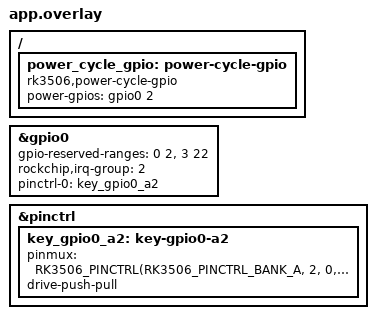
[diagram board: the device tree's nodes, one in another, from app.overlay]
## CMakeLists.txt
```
# SPDX-License-Identifier: Apache-2.0

cmake_minimum_required(VERSION 3.20.0)

get_filename_component(RK3506_ZEPHYR_ROOT
  "${CMAKE_CURRENT_SOURCE_DIR}/../../../.."
  ABSOLUTE
)
# Same compatibility glue as rk3506_pingpong: SDK direct builds invoke this
# as a freestanding app.  NOTE: do NOT append RK3506_ZEPHYR_ROOT to
# EXTRA_ZEPHYR_MODULES here — the repo root exposes zephyr/{CMakeLists.txt,
# Kconfig}, so west's module scanner treats it as a module and re-sources
# the main Kconfig recursively.  BOARD_ROOT/SOC_ROOT/DTS_ROOT below already
# make the board/soc/dts visible.
list(APPEND BOARD_ROOT "${RK3506_ZEPHYR_ROOT}")
list(APPEND SOC_ROOT "${RK3506_ZEPHYR_ROOT}")
list(APPEND DTS_ROOT "${RK3506_ZEPHYR_ROOT}")

find_package(Zephyr REQUIRED HINTS $ENV{ZEPHYR_BASE})
project(gpio_power_cycle)

target_include_directories(app PRIVATE
  src
)

target_sources(app PRIVATE
  src/main.c
)
```

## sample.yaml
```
sample:
  name: RK3506 GPIO0_A2 one-shot key signal
  description: >
    Uses the Zephyr GPIO driver to drive GPIO0_A2:
    HIGH for 50 s -> LOW for 250 ms -> HIGH for 20 s -> LOW for 250 ms -> HIGH indefinitely,
    once per application boot.
tests:
  sample.rk3506.gpio_power_cycle:
    build_only: true
    platform_allow:
      - ok3506b_s12_amp_uart1
    integration_platforms:
      - ok3506b_s12_amp_uart1
```

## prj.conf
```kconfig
# SPDX-License-Identifier: Apache-2.0

CONFIG_SERIAL=y
CONFIG_CONSOLE=y
CONFIG_UART_CONSOLE=y
CONFIG_PRINTK=y
CONFIG_LOG=y

CONFIG_GPIO=y
CONFIG_GPIO_RK3506=y

# This application does not create an RPMsg endpoint.
CONFIG_SOC_RK3506_RPMSG_LITE=n
```

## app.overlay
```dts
/*
 * Copyright (c) 2026
 * SPDX-License-Identifier: Apache-2.0
 *
 * GPIO0_A2 = gpio0 pin 2. Only this pin is assigned to the application.
 */

#include <zephyr/dt-bindings/gpio/gpio.h>

/ {
	power_cycle_gpio: power-cycle-gpio {
		compatible = "rk3506,power-cycle-gpio";
		power-gpios = <&gpio0 2 GPIO_ACTIVE_HIGH>;
	};
};

&gpio0 {
	status = "okay";
	gpio-reserved-ranges = <0 2>, <3 22>;
	rockchip,irq-group = <2>;
	pinctrl-0 = <&key_gpio0_a2>;
	pinctrl-names = "default";
};

&pinctrl {
	key_gpio0_a2: key-gpio0-a2 {
		pinmux = <RK3506_PINCTRL(RK3506_PINCTRL_BANK_A, 2, 0, 0)>;
		drive-push-pull;
	};
};
```

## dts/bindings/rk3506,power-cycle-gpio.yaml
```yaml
# Copyright (c) 2026
# SPDX-License-Identifier: Apache-2.0

description: |
    Single GPIO output used as an external power-controller signal for
    cold power-cycle stress testing.

compatible: "rk3506,power-cycle-gpio"

properties:
  power-gpios:
    type: phandle-array
    required: true
    description: |
      The GPIO that signals the external power controller.
```

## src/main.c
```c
/*
 * Copyright (c) 2026
 * SPDX-License-Identifier: Apache-2.0
 *
 * One-shot key signal: HIGH 50 s, LOW 250 ms, HIGH 20 s, LOW 250 ms, then HIGH.
 * Timing starts when the application configures the GPIO output.
 */

#include <inttypes.h>

#include <zephyr/drivers/gpio.h>
#include <zephyr/kernel.h>
#include <zephyr/logging/log.h>

LOG_MODULE_REGISTER(gpio_power_cycle, LOG_LEVEL_INF);

#if !DT_NODE_EXISTS(DT_NODELABEL(power_cycle_gpio))
#error "power-cycle gpio node missing from devicetree"
#endif

static const struct gpio_dt_spec sig =
	GPIO_DT_SPEC_GET(DT_NODELABEL(power_cycle_gpio), power_gpios);

static int set_level(int level, int64_t start)
{
	int ret = gpio_pin_set_dt(&sig, level);

	if (ret) {
		LOG_ERR("gpio_pin_set_dt(%d) failed: %d", level, ret);
		return ret;
	}
	LOG_INF("t=%" PRId64 " ms GPIO0_A2 -> %s",
		k_uptime_get() - start, level ? "HIGH" : "LOW");
	return 0;
}

int main(void)
{
	int ret;
	int64_t start;
	int64_t phase_start;

	if (!gpio_is_ready_dt(&sig)) {
		LOG_ERR("GPIO device not ready");
		return -ENODEV;
	}

	/* Preload HIGH before enabling the output direction. */
	ret = gpio_pin_configure_dt(&sig, GPIO_OUTPUT_HIGH);
	if (ret) {
		LOG_ERR("configure failed: %d", ret);
		return ret;
	}
	start = k_uptime_get();
	LOG_INF("GPIO0_A2 one-shot: HIGH 50s -> LOW 250ms -> HIGH 20s -> "
		"LOW 250ms -> HIGH forever");
	LOG_INF("t=0 ms GPIO0_A2 -> HIGH (gpio0 pin %u)", sig.pin);

	k_sleep(K_TIMEOUT_ABS_MS(start + 50000));
	ret = set_level(0, start);
	if (ret != 0) {
		return ret;
	}
	phase_start = k_uptime_get();
	k_sleep(K_TIMEOUT_ABS_MS(phase_start + 250));
	ret = set_level(1, start);
	if (ret != 0) {
		return ret;
	}
	phase_start = k_uptime_get();
	k_sleep(K_TIMEOUT_ABS_MS(phase_start + 20000));
	ret = set_level(0, start);
	if (ret != 0) {
		return ret;
	}
	phase_start = k_uptime_get();
	k_sleep(K_TIMEOUT_ABS_MS(phase_start + 250));
	ret = set_level(1, start);
	if (ret != 0) {
		return ret;
	}
	LOG_INF("one-shot complete; GPIO0_A2 stays HIGH, no repeat");

	return 0;
}
```
